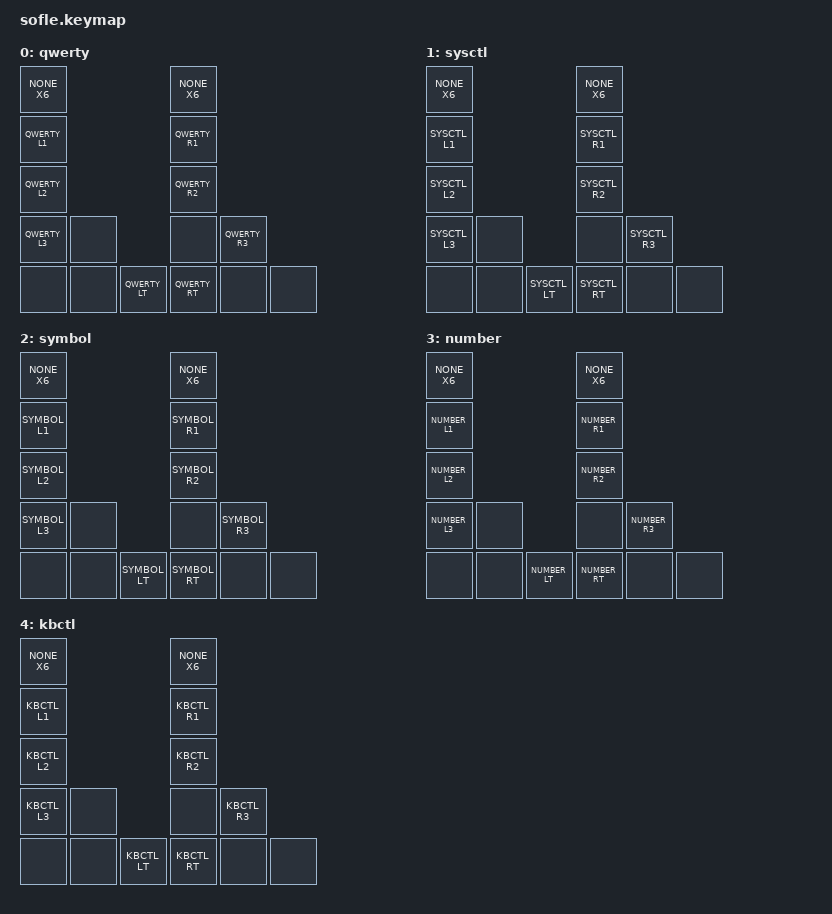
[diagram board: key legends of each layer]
#include <behaviors.dtsi>
#include <dt-bindings/zmk/keys.h>
#include <dt-bindings/zmk/bt.h>
#include <dt-bindings/zmk/outputs.h>
#include <dt-bindings/zmk/rgb.h>

#include "pvinis_keys.dtsi"
#include "pvinis_behaviors.dtsi"
#include "pvinis_split_layers.dtsi"

// Same layout as the Corne (see pvinis_split_layers.dtsi). The Sofle's extra keys, the number
// row, the two encoder clicks and the outer two thumb keys on each side, are deliberately unused.
// The Corne's three thumb keys sit on the three innermost of the Sofle's five.
// Only the encoders' rotation is Sofle-specific: left is volume, right is Spotify volume
// (page up/down on sysctl).
// Drawing: keymap-drawer/sofle.svg

/ {
	// activate KBCTL layer by pressing SYSCTL and SYMBOL
	conditional_layers {
		compatible = "zmk,conditional-layers";
		adjust_layer {
			if-layers = <SYSCTL SYMBOL>;
			then-layer = <KBCTL>;
		};
	};

	keymap {
		compatible = "zmk,keymap";

		qwerty_layer {
			display-name = "qwerty";
			bindings = <
			NONE_X6                  NONE_X6
			QWERTY_L1                QWERTY_R1
			QWERTY_L2                QWERTY_R2
			QWERTY_L3  &none    &none  QWERTY_R3
			&none  &none  QWERTY_LT      QWERTY_RT  &none  &none
			>;

			sensor-bindings = <&inc_dec_kp C_VOL_UP C_VOL_DN &inc_dec_kp PV_SP_VOLU PV_SP_VOLD>;
		};

		sysctl_layer {
			display-name = "sysctl";
			bindings = <
			NONE_X6                  NONE_X6
			SYSCTL_L1                SYSCTL_R1
			SYSCTL_L2                SYSCTL_R2
			SYSCTL_L3  &none    &none  SYSCTL_R3
			&none  &none  SYSCTL_LT      SYSCTL_RT  &none  &none
			>;

			sensor-bindings = <&inc_dec_kp C_VOL_UP C_VOL_DN &inc_dec_kp PG_UP PG_DN>;
		};

		symbol_layer {
			display-name = "symbol";
			bindings = <
			NONE_X6                  NONE_X6
			SYMBOL_L1                SYMBOL_R1
			SYMBOL_L2                SYMBOL_R2
			SYMBOL_L3  &none    &none  SYMBOL_R3
			&none  &none  SYMBOL_LT      SYMBOL_RT  &none  &none
			>;

			sensor-bindings = <&inc_dec_kp C_VOL_UP C_VOL_DN &inc_dec_kp PV_SP_VOLU PV_SP_VOLD>;
		};

		number_layer {
			display-name = "number";
			bindings = <
			NONE_X6                  NONE_X6
			NUMBER_L1                NUMBER_R1
			NUMBER_L2                NUMBER_R2
			NUMBER_L3  &none    &none  NUMBER_R3
			&none  &none  NUMBER_LT      NUMBER_RT  &none  &none
			>;

			sensor-bindings = <&inc_dec_kp C_VOL_UP C_VOL_DN &inc_dec_kp PV_SP_VOLU PV_SP_VOLD>;
		};

		kbctl_layer {
			display-name = "kbctl";
			bindings = <
			NONE_X6                  NONE_X6
			KBCTL_L1                KBCTL_R1
			KBCTL_L2                KBCTL_R2
			KBCTL_L3  &none    &none  KBCTL_R3
			&none  &none  KBCTL_LT      KBCTL_RT  &none  &none
			>;

			sensor-bindings = <&inc_dec_kp C_VOL_UP C_VOL_DN &inc_dec_kp PV_SP_VOLU PV_SP_VOLD>;
		};
	};
};


// TODO: oleds (see issue #11)
// TODO: try hjkl instead of arrow keys
// TODO: rotaries
// TODO: home row mods
// TODO: game mode
// TODO: screenshot button
// TODO: spotify encoder
